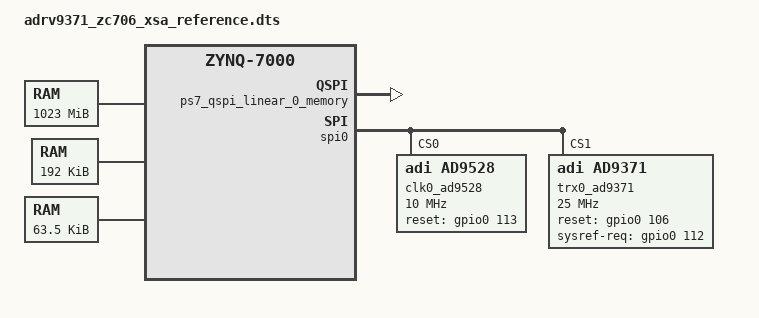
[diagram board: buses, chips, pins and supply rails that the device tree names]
/*
 * ADI Device Tree (merged) — adrv937x_zc706
 *
 * Generated by pyadi-dt from XSA. Do not edit manually — re-run
 * the pipeline to regenerate from the XSA source.
 *
 * Compile with:
 *   dtc -I dts -O dtb -o system.dtb adrv937x_zc706.dts
 */
/dts-v1/;
#include "zynq-7000.dtsi"
#include "pl.dtsi"
#include "pcw.dtsi"
/delete-node/ &axi_hdmi_clkgen;

/ {
	board = "zc706";
	compatible = "xlnx,zynq-7000";
	device_id = "7z045";
	slrcount = <1>;
	family = "Zynq";
	speed_grade = "2";
	ps7_qspi_linear_0_memory: memory@fc000000 {
		compatible = "xlnx,ps7-qspi-linear-1.00.a-memory";
		xlnx,ip-name = "ps7_qspi_linear";
		memory_type = "linear_flash";
		reg = <0xfc000000 0x2000000>;
	};
	ps7_ddr_0_memory: memory@00100000 {
		compatible = "xlnx,ps7-ddr-1.00.a";
		xlnx,ip-name = "ps7_ddr";
		device_type = "memory";
		memory_type = "memory";
		reg = <0x00100000 0x3FF00000>;
	};
	ps7_ram_0_memory: memory@0 {
		compatible = "xlnx,ps7-ram-1.00.a";
		xlnx,ip-name = "ps7_ram";
		memory_type = "memory";
		reg = <0x0 0x30000>;
	};
	ps7_ram_1_memory: memory@ffff0000 {
		compatible = "xlnx,ps7-ram-1.00.a";
		xlnx,ip-name = "ps7_ram";
		memory_type = "memory";
		reg = <0xffff0000 0xfe00>;
	};
	chosen {
		stdout-path = "serial0:115200n8";
		bootargs = "earlycon";
	};
	aliases {
		serial0 = &uart1;
		spi0 = &qspi;
		serial1 = &coresight;
		i2c0 = &axi_iic_main;
		i2c1 = &i2c0;
		ethernet0 = &gem0;
	};
	cpus_a9: cpus-a9@0 {
		compatible = "cpus,cluster";
		address-map = <0xf0000000 &amba 0xf0000000 0x10000000>, 
			      <0x00100000 &ps7_ddr_0_memory 0x00100000 0x3FF00000>, 
			      <0x0 &ps7_ram_0_memory 0x0 0x30000>, 
			      <0xffff0000 &ps7_ram_1_memory 0xffff0000 0xfe00>, 
			      <0x41600000 &axi_iic_main 0x41600000 0x1000>, 
			      <0x43000000 &axi_hdmi_dma 0x43000000 0x1000>, 
			      <0x43c00000 &axi_ad9371_tx_clkgen 0x43c00000 0x10000>, 
			      <0x43c10000 &axi_ad9371_rx_clkgen 0x43c10000 0x10000>, 
			      <0x43c20000 &axi_ad9371_rx_os_clkgen 0x43c20000 0x10000>, 
			      <0x44a00000 &rx_ad9371_tpl_core_adc_tpl_core 0x44a00000 0x2000>, 
			      <0x44a04000 &tx_ad9371_tpl_core_dac_tpl_core 0x44a04000 0x2000>, 
			      <0x44a08000 &rx_os_ad9371_tpl_core_adc_tpl_core 0x44a08000 0x2000>, 
			      <0x44a50000 &axi_ad9371_rx_os_xcvr 0x44a50000 0x10000>, 
			      <0x44a60000 &axi_ad9371_rx_xcvr 0x44a60000 0x10000>, 
			      <0x44a80000 &axi_ad9371_tx_xcvr 0x44a80000 0x10000>, 
			      <0x44a90000 &axi_ad9371_tx_jesd_tx_axi 0x44a90000 0x4000>, 
			      <0x44aa0000 &axi_ad9371_rx_jesd_rx_axi 0x44aa0000 0x4000>, 
			      <0x44ab0000 &axi_ad9371_rx_os_jesd_rx_axi 0x44ab0000 0x4000>, 
			      <0x45000000 &axi_sysid_0 0x45000000 0x10000>, 
			      <0x70e00000 &axi_hdmi_core 0x70e00000 0x10000>, 
			      <0x75c00000 &axi_spdif_tx_core 0x75c00000 0x10000>, 
			      <0x79000000 &axi_hdmi_clkgen 0x79000000 0x10000>, 
			      <0x7c400000 &axi_ad9371_rx_dma 0x7c400000 0x1000>, 
			      <0x7c420000 &axi_ad9371_tx_dma 0x7c420000 0x1000>, 
			      <0x7c440000 &axi_ad9371_rx_os_dma 0x7c440000 0x1000>, 
			      <0xf8008000 &ps7_afi_0 0xf8008000 0x1000>, 
			      <0xf8009000 &ps7_afi_1 0xf8009000 0x1000>, 
			      <0xf800a000 &ps7_afi_2 0xf800a000 0x1000>, 
			      <0xf800b000 &ps7_afi_3 0xf800b000 0x1000>, 
			      <0xf8800000 &coresight 0xf8800000 0x100000>, 
			      <0xf8006000 &mc 0xf8006000 0x1000>, 
			      <0xf8007000 &devcfg 0xf8007000 0x100>, 
			      <0xf8004000 &ps7_dma_ns 0xf8004000 0x1000>, 
			      <0xf8003000 &dmac_s 0xf8003000 0x1000>, 
			      <0xe000b000 &gem0 0xe000b000 0x1000>, 
			      <0xf8f00200 &global_timer 0xf8f00200 0x100>, 
			      <0xe000a000 &gpio0 0xe000a000 0x1000>, 
			      <0xf8900000 &ps7_gpv_0 0xf8900000 0x100000>, 
			      <0xe0004000 &i2c0 0xe0004000 0x1000>, 
			      <0xf8f01000 &intc 0xf8f01000 0x1000>, 
			      <0xe0200000 &ps7_iop_bus_config_0 0xe0200000 0x1000>, 
			      <0xf8f02000 &L2 0xf8f02000 0x1000>, 
			      <0xf800c000 &ps7_ocmc_0 0xf800c000 0x1000>, 
			      <0xf8891000 &ps7_pmu_0 0xf8891000 0x1000>, 
			      <0xe000d000 &qspi 0xe000d000 0x1000>, 
			      <0xfc000000 &ps7_qspi_linear_0_memory 0xfc000000 0x2000000>, 
			      <0xf8f00000 &ps7_scuc_0 0xf8f00000 0xfd>, 
			      <0xf8f00600 &scutimer 0xf8f00600 0x20>, 
			      <0xf8f00620 &scuwdt 0xf8f00620 0xe0>, 
			      <0xe0100000 &sdhci0 0xe0100000 0x1000>, 
			      <0xf8000000 &slcr 0xf8000000 0x1000>, 
			      <0xe0006000 &spi0 0xe0006000 0x1000>, 
			      <0xe0007000 &spi1 0xe0007000 0x1000>, 
			      <0xe0001000 &uart1 0xe0001000 0x1000>, 
			      <0xe0002000 &usb0 0xe0002000 0x1000>, 
			      <0xf8007100 &adc 0xf8007100 0x21>;
		#ranges-address-cells = <0x1>;
		#ranges-size-cells = <0x1>;
	};
};

&amba {
	/* --- Clock Generators --- */
	axi_hdmi_clkgen: axi-clkgen@79000000 {
		compatible = "adi,axi-clkgen-2.00.a";
		reg = <0x79000000 0x10000>;
		#clock-cells = <1>;
		clocks = <&clkc 15>, <&clkc 15>;
		clock-names = "clkin1", "s_axi_aclk";
		clock-output-names = "axi_hdmi_clkgen_0", "axi_hdmi_clkgen_1";
	};
};

	&misc_clk_0 {
		compatible = "fixed-clock";
		#clock-cells = <0>;
		clock-frequency = <122880000>;
	};
	&axi_ad9371_rx_clkgen {
		compatible = "adi,axi-clkgen-2.00.a";
		#clock-cells = <0>;
		clock-output-names = "axi_ad9371_rx_clkgen";
		clock-names = "clkin1", "s_axi_aclk";
	};
	&axi_ad9371_tx_clkgen {
		compatible = "adi,axi-clkgen-2.00.a";
		#clock-cells = <0>;
		clock-output-names = "axi_ad9371_tx_clkgen";
		clock-names = "clkin1", "s_axi_aclk";
	};
	&axi_ad9371_rx_xcvr {
		compatible = "adi,axi-adxcvr-1.0";
		clocks = <&clk0_ad9528 1>;
		clock-names = "conv";
		#clock-cells = <1>;
		clock-output-names = "rx_gt_clk", "rx_out_clk";
		adi,sys-clk-select = <0>;
		adi,out-clk-select = <3>;
		adi,use-lpm-enable;
		jesd204-device;
		#jesd204-cells = <2>;
		jesd204-inputs = <&clk0_ad9528 0 1>;
	};
	&axi_ad9371_tx_xcvr {
		compatible = "adi,axi-adxcvr-1.0";
		clocks = <&clk0_ad9528 1>;
		clock-names = "conv";
		#clock-cells = <1>;
		clock-output-names = "tx_gt_clk", "tx_out_clk";
		adi,sys-clk-select = <3>;
		adi,out-clk-select = <3>;
		jesd204-device;
		#jesd204-cells = <2>;
		jesd204-inputs = <&clk0_ad9528 0 0>;
	};
	&rx_ad9371_tpl_core_adc_tpl_core {
		compatible = "adi,axi-ad9371-rx-1.0";
		adi,axi-decimation-core-available;
		dmas = <&axi_ad9371_rx_dma 0>;
		dma-names = "rx";
	};
	&tx_ad9371_tpl_core_dac_tpl_core {
		compatible = "adi,axi-ad9371-tx-1.0";
		adi,axi-interpolation-core-available;
		dmas = <&axi_ad9371_tx_dma 0>;
		dma-names = "tx";
		clocks = <&clkc 15>;
		clock-names = "sampl_clk";
	};
	&axi_ad9371_rx_os_clkgen {
		compatible = "adi,axi-clkgen-2.00.a";
		#clock-cells = <0>;
		clock-output-names = "axi_ad9371_rx_os_clkgen";
		clock-names = "clkin1", "s_axi_aclk";
	};
	&axi_ad9371_rx_os_xcvr {
		compatible = "adi,axi-adxcvr-1.0";
		clocks = <&clk0_ad9528 1>;
		clock-names = "conv";
		#clock-cells = <1>;
		clock-output-names = "rx_os_gt_clk", "rx_os_out_clk";
		adi,sys-clk-select = <0>;
		adi,out-clk-select = <3>;
		adi,use-lpm-enable;
		jesd204-device;
		#jesd204-cells = <2>;
		jesd204-inputs = <&clk0_ad9528 0 2>;
	};
	&axi_ad9371_rx_os_jesd_rx_axi {
		/delete-property/ compatible;
		/delete-property/ clocks;
		/delete-property/ clock-names;
		/delete-property/ #clock-cells;
		/delete-property/ adi,octets-per-frame;
		/delete-property/ adi,frames-per-multiframe;
		#clock-cells = <0>;
		#jesd204-cells = <2>;
		jesd204-device;
		clocks = <&clkc 15>, <&axi_ad9371_rx_os_clkgen>, <&axi_ad9371_rx_os_xcvr 0>;
		clock-names = "s_axi_aclk", "device_clk", "lane_clk";
		clock-output-names = "jesd_rx_os_lane_clk";
		jesd204-inputs = <&axi_ad9371_rx_os_xcvr 0 2>;
		compatible = "adi,axi-jesd204-rx-1.0";
		adi,octets-per-frame = <2>;
		adi,frames-per-multiframe = <32>;
	};
	&rx_os_ad9371_tpl_core_adc_tpl_core {
		/delete-property/ compatible;
		compatible = "adi,axi-ad9371-obs-1.0";
		dmas = <&axi_ad9371_rx_os_dma 0>;
		dma-names = "rx";
		spibus-connected = <&trx0_ad9371>;
		clocks = <&trx0_ad9371 1>;
		clock-names = "sampl_clk";
	};
	&spi0 {
		status = "okay";
		#address-cells = <1>;
		#size-cells = <0>;
		clk0_ad9528: ad9528-1@0 {
			compatible = "adi,ad9528";
			#address-cells = <1>;
			#size-cells = <0>;
			#clock-cells = <1>;
			adi,pll1-feedback-div = <4>;
			adi,pll1-charge-pump-current-nA = <5000>;
			adi,pll2-vco-div-m1 = <3>;
			adi,pll2-n2-div = <10>;
			adi,pll2-r1-div = <1>;
			adi,pll2-charge-pump-current-nA = <805000>;
			adi,refa-r-div = <1>;
			adi,sysref-src = <2>;
			adi,sysref-pattern-mode = <0>;
			adi,sysref-k-div = <512>;
			adi,sysref-nshot-mode = <3>;
			adi,sysref-request-trigger-mode = <0>;
			adi,status-mon-pin0-function-select = <1>;
			adi,status-mon-pin1-function-select = <7>;
			adi,rpole2 = <0>;
			adi,rzero = <7>;
			adi,cpole1 = <2>;
			adi,refa-enable;
			adi,refa-diff-rcv-enable;
			adi,osc-in-cmos-neg-inp-enable;
			reg = <0>;
			reset-gpios = <&gpio0 113 0>;
			jesd204-device;
			#jesd204-cells = <2>;
			jesd204-sysref-provider;
			adi,jesd204-max-sysref-frequency-hz = <78125>;
			spi-max-frequency = <10000000>;
			adi,vcxo-freq = <122880000>;
			clock-output-names = "ad9528-1_out0", "ad9528-1_out1", "ad9528-1_out2", "ad9528-1_out3", "ad9528-1_out4", "ad9528-1_out5", "ad9528-1_out6", "ad9528-1_out7", "ad9528-1_out8", "ad9528-1_out9", "ad9528-1_out10", "ad9528-1_out11", "ad9528-1_out12", "ad9528-1_out13";
			ad9528_0_c1: channel@1 {
				adi,driver-mode = <0>;
				adi,divider-phase = <0>;
				reg = <1>;
				adi,extended-name = "FMC_CLK";
				adi,channel-divider = <10>;
				adi,signal-source = <0>;
			};
			ad9528_0_c3: channel@3 {
				adi,driver-mode = <0>;
				adi,divider-phase = <0>;
				reg = <3>;
				adi,extended-name = "FMC_SYSREF";
				adi,channel-divider = <10>;
				adi,signal-source = <2>;
			};
			ad9528_0_c12: channel@12 {
				adi,driver-mode = <0>;
				adi,divider-phase = <0>;
				reg = <12>;
				adi,extended-name = "DEV_SYSREF";
				adi,channel-divider = <10>;
				adi,signal-source = <2>;
			};
			ad9528_0_c13: channel@13 {
				adi,driver-mode = <0>;
				adi,divider-phase = <0>;
				reg = <13>;
				adi,extended-name = "DEV_CLK";
				adi,channel-divider = <10>;
				adi,signal-source = <0>;
			};
		};		trx0_ad9371: ad9371-phy@1 {
			#clock-cells = <1>;
			clock-output-names = "rx_sampl_clk", "rx_os_sampl_clk", "tx_sampl_clk";
			#jesd204-cells = <2>;
			jesd204-top-device = <0>;
			jesd204-device;
			reg = <1>;
			clocks = <&axi_ad9371_rx_jesd_rx_axi>, <&axi_ad9371_tx_jesd_tx_axi>, <&axi_ad9371_rx_os_jesd_rx_axi>, <&clk0_ad9528 13>, <&clk0_ad9528 1>, <&clk0_ad9528 12>, <&clk0_ad9528 3>;
			clock-names = "jesd_rx_clk", "jesd_tx_clk", "jesd_rx_os_clk", "dev_clk", "fmc_clk", "sysref_dev_clk", "sysref_fmc_clk";
			reset-gpios = <&gpio0 106 0>;
			sysref-req-gpios = <&gpio0 112 0>;
			jesd204-link-ids = <0 1 2>;
			jesd204-inputs = <&axi_ad9371_rx_jesd_rx_axi 0 1>, <&axi_ad9371_rx_os_jesd_rx_axi 0 2>, <&axi_ad9371_tx_jesd_tx_axi 0 0>;
			compatible = "adi,ad9371";
			spi-max-frequency = <25000000>;
			adi,clocks-clk-pll-vco-freq_khz = <0x960000>;
			adi,clocks-device-clock_khz = <0x1e000>;
			adi,clocks-clk-pll-hs-div = <0x04>;
			adi,clocks-clk-pll-vco-div = <0x02>;
			adi,jesd204-obs-framer-over-sample = <0x00>;
			adi,rx-profile-adc-div = <0x01>;
			adi,rx-profile-en-high-rej-dec5 = <0x01>;
			adi,rx-profile-iq-rate_khz = <0x1e000>;
			adi,rx-profile-rf-bandwidth_hz = <0x5f5e100>;
			adi,rx-profile-rhb1-decimation = <0x01>;
			adi,rx-profile-rx-bbf-3db-corner_khz = <0x186a0>;
			adi,rx-profile-rx-dec5-decimation = <0x05>;
			adi,rx-profile-rx-fir-decimation = <0x02>;
			adi,rx-profile-rx-fir-gain_db = <0xfffffffa>;
			adi,rx-profile-rx-fir-num-fir-coefs = <0x30>;
			adi,rx-profile-rx-fir-coefs = <0xfffbffe6 0x200033 0xffbdff8c 0x8c00d4 0xff04fe91 0x1ad0253 0xfd50fc5d 0x4300593 0xf98ef774 0xa340da8 0xed3ee259 0x25b87e3d 0x7e3d25b8 0xe259ed3e 0xda80a34 0xf774f98e 0x5930430 0xfc5dfd50 0x25301ad 0xfe91ff04 0xd4008c 0xff8cffbd 0x330020 0xffe6fffb>;
			adi,rx-profile-custom-adc-profile = <0x2160182 0xc90062 0x50001eb 0x6370117 0x51a0068 0x318001c 0x300027 0x1700bb>;
			adi,obs-profile-adc-div = <0x01>;
			adi,obs-profile-en-high-rej-dec5 = <0x01>;
			adi,obs-profile-iq-rate_khz = <0x3c000>;
			adi,obs-profile-rf-bandwidth_hz = <0xbebc200>;
			adi,obs-profile-rhb1-decimation = <0x01>;
			adi,obs-profile-rx-bbf-3db-corner_khz = <0x186a0>;
			adi,obs-profile-rx-dec5-decimation = <0x05>;
			adi,obs-profile-rx-fir-decimation = <0x01>;
			adi,obs-profile-rx-fir-gain_db = <0x06>;
			adi,obs-profile-rx-fir-num-fir-coefs = <0x18>;
			adi,obs-profile-rx-fir-coefs = <0xfedf0051 0xffe9ffaa 0xe5fe9e 0x18dff17 0xfd6f06a3 0xefb459e2 0xefb406a3 0xfd6fff17 0x18dfe9e 0xe5ffaa 0xffe90051 0xfedf0000>;
			adi,obs-profile-custom-adc-profile = <0x1c2015d 0xc90062 0x50002da 0x65a0332 0x5c402dc 0x3420014 0x290024 0x1800c8>;
			adi,obs-settings-custom-loopback-adc-profile = <0x2390171 0xc90062 0x5000123 0x6050095 0x528003a 0x3270022 0x300028 0x1700bd>;
			adi,tx-profile-dac-div = <0x01>;
			adi,tx-profile-iq-rate_khz = <0x3c000>;
			adi,tx-profile-primary-sig-bandwidth_hz = <0x47868c0>;
			adi,tx-profile-rf-bandwidth_hz = <0xbebc200>;
			adi,tx-profile-thb1-interpolation = <0x02>;
			adi,tx-profile-thb2-interpolation = <0x01>;
			adi,tx-profile-tx-bbf-3db-corner_khz = <0x186a0>;
			adi,tx-profile-tx-dac-3db-corner_khz = <0x2da78>;
			adi,tx-profile-tx-fir-interpolation = <0x01>;
			adi,tx-profile-tx-input-hb-interpolation = <0x01>;
			adi,tx-profile-tx-fir-gain_db = <0x06>;
			adi,tx-profile-tx-fir-num-fir-coefs = <0x10>;
			adi,tx-profile-tx-fir-coefs = <0x6fef2 0xcbff58 0xffac03d7 0xf36a5297 0xf36a03d7 0xffacff58 0xcbfef2 0x60000>;
			adi,sniffer-profile-adc-div = <0x01>;
			adi,sniffer-profile-en-high-rej-dec5 = <0x00>;
			adi,sniffer-profile-iq-rate_khz = <0x7800>;
			adi,sniffer-profile-rf-bandwidth_hz = <0x1312d00>;
			adi,sniffer-profile-rhb1-decimation = <0x02>;
			adi,sniffer-profile-rx-bbf-3db-corner_khz = <0x186a0>;
			adi,sniffer-profile-rx-dec5-decimation = <0x05>;
			adi,sniffer-profile-rx-fir-decimation = <0x04>;
		};
	};
	&axi_ad9371_rx_dma {
		/delete-property/ compatible;
		compatible = "adi,axi-dmac-1.00.a";
		#dma-cells = <1>;
		#clock-cells = <0>;
	};
	&axi_ad9371_tx_dma {
		/delete-property/ compatible;
		compatible = "adi,axi-dmac-1.00.a";
		#dma-cells = <1>;
		#clock-cells = <0>;
	};
	&axi_ad9371_rx_jesd_rx_axi {
		/delete-property/ compatible;
		/delete-property/ clocks;
		/delete-property/ clock-names;
		/delete-property/ #clock-cells;
		/delete-property/ adi,octets-per-frame;
		/delete-property/ adi,frames-per-multiframe;
		#clock-cells = <0>;
		#jesd204-cells = <2>;
		jesd204-device;
		clocks = <&clkc 15>, <&axi_ad9371_rx_clkgen>, <&axi_ad9371_rx_xcvr 0>;
		clock-names = "s_axi_aclk", "device_clk", "lane_clk";
		clock-output-names = "jesd_rx_lane_clk";
		jesd204-inputs = <&axi_ad9371_rx_xcvr 0 1>;
		compatible = "adi,axi-jesd204-rx-1.0";
		adi,octets-per-frame = <4>;
		adi,frames-per-multiframe = <32>;
	};
	&axi_ad9371_tx_jesd_tx_axi {
		/delete-property/ compatible;
		/delete-property/ clocks;
		/delete-property/ clock-names;
		/delete-property/ #clock-cells;
		/delete-property/ adi,octets-per-frame;
		/delete-property/ adi,frames-per-multiframe;
		#clock-cells = <0>;
		#jesd204-cells = <2>;
		jesd204-device;
		clocks = <&clkc 15>, <&axi_ad9371_tx_clkgen>, <&axi_ad9371_tx_xcvr 0>;
		clock-names = "s_axi_aclk", "device_clk", "lane_clk";
		clock-output-names = "jesd_tx_lane_clk";
		jesd204-inputs = <&axi_ad9371_tx_xcvr 0 0>;
		compatible = "adi,axi-jesd204-tx-1.0";
		adi,octets-per-frame = <2>;
		adi,frames-per-multiframe = <32>;
		adi,converter-resolution = <14>;
		adi,bits-per-sample = <16>;
		adi,converters-per-device = <4>;
		adi,control-bits-per-sample = <2>;
	};
	&rx_ad9371_tpl_core_adc_tpl_core {
		spibus-connected = <&trx0_ad9371>;
	};
	&tx_ad9371_tpl_core_dac_tpl_core {
		spibus-connected = <&trx0_ad9371>;
		clocks = <&trx0_ad9371 2>;
		clock-names = "sampl_clk";
	};
